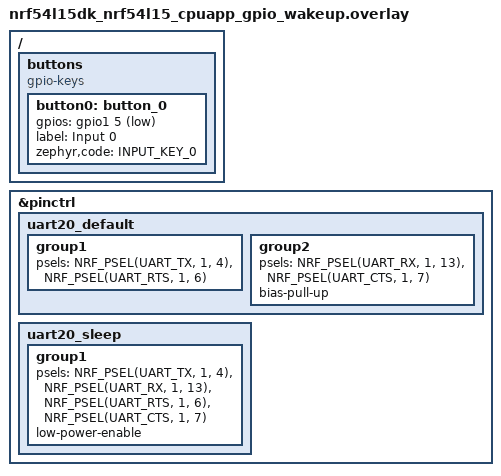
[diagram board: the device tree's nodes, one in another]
/ {
	/*
	 * Redefine sw0/button0 to use RXD1 - P1.05
	 * Thus, when sending character from host, there will be gpio interrupt,
	 * the same as originally triggered by sw0 button.
	 */
	 buttons {
		compatible = "gpio-keys";
		button0: button_0 {
			gpios = <&gpio1 5 (GPIO_PULL_UP | GPIO_ACTIVE_LOW)>;
			label = "Input 0";
			zephyr,code = <INPUT_KEY_0>;
		};
	};
};

&pinctrl {
	/*
	* Redefine: RXD1 -> P1.13 (button0)
	*/
	/omit-if-no-ref/ uart20_default: uart20_default {
		group1 {
			psels = <NRF_PSEL(UART_TX, 1, 4)>,
				<NRF_PSEL(UART_RTS, 1, 6)>;
		};
		group2 {
			psels = <NRF_PSEL(UART_RX, 1, 13)>,
				<NRF_PSEL(UART_CTS, 1, 7)>;
			bias-pull-up;
		};
	};

	/omit-if-no-ref/ uart20_sleep: uart20_sleep {
		group1 {
			psels = <NRF_PSEL(UART_TX, 1, 4)>,
				<NRF_PSEL(UART_RX, 1, 13)>,
				<NRF_PSEL(UART_RTS, 1, 6)>,
				<NRF_PSEL(UART_CTS, 1, 7)>;
			low-power-enable;
		};
	};
};
